# CH32H417 register map
Vendor: WCH Ltd.; File version: 1.2
Registers are 32-bit, read-write, reset 0x0 unless marked. A register's access mark holds for its fields unless they carry their own. Offsets are from the block's base; [hi:lo] are bit positions.

## ESIG — ESIG configuration
Base 0x1FFFF7E0
0x00 FLACAP 16-bit ro — Flash capecity register
  [15:0] F_SIZE — F_SIZE/kByte
0x08 UNIID1 ro — UID register
  [31:0] U_ID — U_ID value
0x0C UNIID2 ro — UID register
  [31:0] U_ID — U_ID value
0x10 UNIID3 ro — Div register
  [31:0] U_ID — U_ID value

## TIM6 — Basic timer
Base 0x40001000
Same registers: TIM7 0x40001400
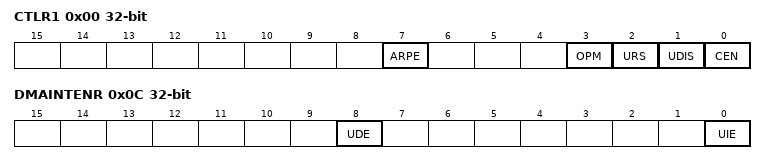
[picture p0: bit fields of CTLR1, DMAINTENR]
0x00 CTLR1 — control register 1
  [7] ARPE — Auto-reload preload enable
  [3] OPM — One-pulse mode
  [2] URS — Update request source
  [1] UDIS — Update disable
  [0] CEN — Counter enable
0x04 CTLR2 — control register 2
  [6:4] MMS — Master mode selection
0x0C DMAINTENR — DMA/Interrupt enable register
  [8] UDE — Update DMA request enable
  [0] UIE — Update interrupt enable
0x10 INTFR — status register
  [0] UIF — Update interrupt flag
0x14 SWEVGR wo — event generation register
  [0] UG — Update generation
0x24 CNT — counter
  [15:0] CNT — counter value
0x28 PSC — prescaler
  [15:0] PSC — Prescaler value
0x2C ATRLR reset 0xFFFF — auto-reload register
  [15:0] ARR — Auto-reload value

## LPTIM1 — Low-power timer 1
Base 0x40002400
Same registers: LPTIM2 0x40003400
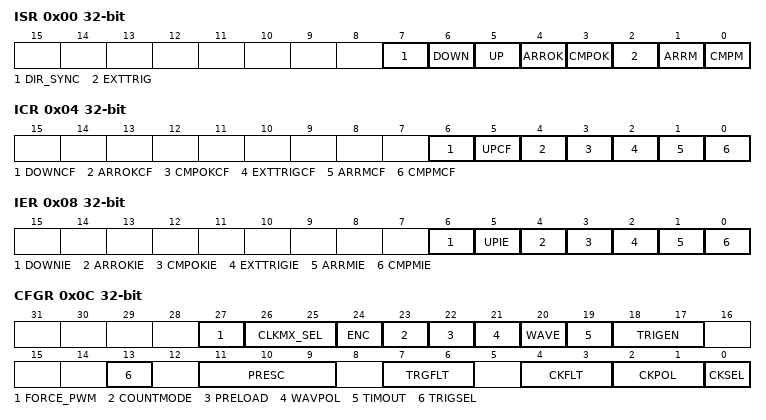
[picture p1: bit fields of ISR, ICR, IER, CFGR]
0x00 ISR ro — interrupt status register
  [7] DIR_SYNC — direction of count
  [6] DOWN — count down
  [5] UP — count-up
  [4] ARROK — Aoto-reload register data update successfully
  [3] CMPOK — compare register data update successfully
  [2] EXTTRIG — Edge event are triggerd externally
  [1] ARRM — DATA of Aoto-reload register and LPTIM_CNT match
  [0] CMPM — DATA of compare register and LPTIM_CNT match
0x04 ICR wo — interrupt clear register
  [6] DOWNCF — clear down flag
  [5] UPCF — clear up flag
  [4] ARROKCF — clear Aoto-reload register data update flag
  [3] CMPOKCF — clear compare register data update flag
  [2] EXTTRIGCF — clear Edge event are triggerd externally flag
  [1] ARRMCF — clear Aoto-reload register match flag
  [0] CMPMCF — clear compare register match flag
0x08 IER — interrupt enable register
  [6] DOWNIE — Down interrupt enable
  [5] UPIE — UP interrupt enable
  [4] ARROKIE — Aoto-reload register data update successfully interrupts enable
  [3] CMPOKIE — compare register data update successfully interrupts enable
  [2] EXTTRIGIE — Edge event are triggerd externally successfully interrupts enable
  [1] ARRMIE — Aoto-reload register match successfully interrupts enable
  [0] CMPMIE — compare register match successfully interrupts enable
0x0C CFGR — configuration register
  [27] FORCE_PWM — Forcing pwm output
  [26:25] CLKMX_SEL — clock selection
  [24] ENC — coder mode
  [23] COUNTMODE — count clock selection
  [22] PRELOAD — update mode control
  [21] WAVPOL — PWM polarity
  [20] WAVE — PWM
  [19] TIMOUT — TIMEOUT control
  [18:17] TRIGEN — trigger configuration
  [13] TRIGSEL — trigger source selection
  [11:9] PRESC — prescaler configuration
  [7:6] TRGFLT — digital filter for flip-flops
  [4:3] CKFLT — digital filter for ex-clock
  [2:1] CKPOL — configure effective edges
  [0] CKSEL — effective edge configuration
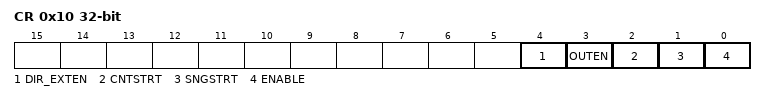
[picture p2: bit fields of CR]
0x10 CR — control register
  [4] DIR_EXTEN — externally trigger count direction enable
  [3] OUTEN — pwm output enable
  [2] CNTSTRT — start in continuous mode
  [1] SNGSTRT — start in one trigger mode
  [0] ENABLE — timer enable
0x14 CMP — compare register
  [15:0] CMP — compare value
0x18 ARR reset 0x1 — aoto-reload register
  [15:0] ARR — aoto-reload count value
0x1C CNT — COUNT register
  [15:0] COUNT — Timer count value

## DAC — Digital to analog converter
Base 0x40007400
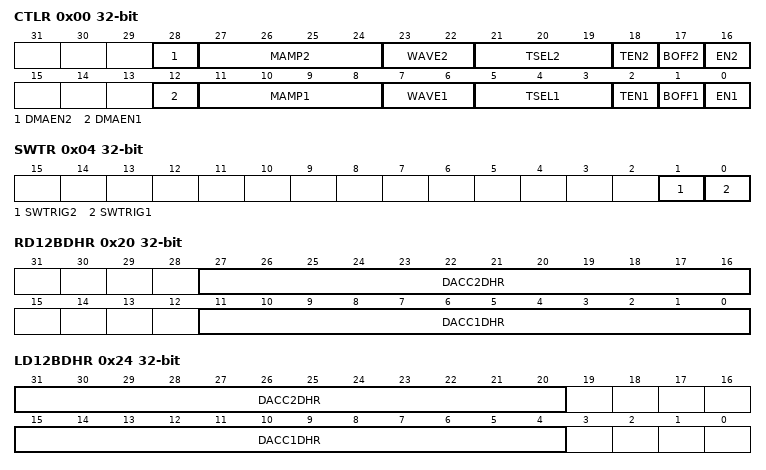
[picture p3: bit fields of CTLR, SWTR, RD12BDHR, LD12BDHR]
0x00 CTLR — Control register (DAC_CR)
  [28] DMAEN2 — DAC channel2 DMA enable
  [27:24] MAMP2 — DAC channel2 mask/amplitude selector
  [23:22] WAVE2 — DAC channel2 noise/triangle wave generation enable
  [21:19] TSEL2 — DAC channel2 trigger selection
  [18] TEN2 — DAC channel2 trigger enable
  [17] BOFF2 — DAC channel2 output buffer disable
  [16] EN2 — DAC channel2 enable
  [12] DMAEN1 — DAC channel1 DMA enable
  [11:8] MAMP1 — DAC channel1 mask/amplitude selector
  [7:6] WAVE1 — DAC channel1 noise/triangle wave generation enable
  [5:3] TSEL1 — DAC channel1 trigger selection
  [2] TEN1 — DAC channel1 trigger enable
  [1] BOFF1 — DAC channel1 output buffer disable
  [0] EN1 — DAC channel1 enable
0x04 SWTR wo — DAC software trigger register (DAC_SWTRIGR)
  [1] SWTRIG2 — DAC channel2 software trigger
  [0] SWTRIG1 — DAC channel1 software trigger
0x08 R12BDHR1 — DAC channel1 12-bit right-aligned data holding register(DAC_DHR12R1)
  [11:0] DACC1DHR — DAC channel1 12-bit right-aligned data
0x0C L12BDHR1 — DAC channel1 12-bit left aligned data holding register (DAC_DHR12L1)
  [15:4] DACC1DHR — DAC channel1 12-bit left-aligned data
0x10 R8BDHR1 — DAC channel1 8-bit right aligned data holding register (DAC_DHR8R1)
  [7:0] DACC1DHR — DAC channel1 8-bit right-aligned data
0x14 R12BDHR2 — DAC channel2 12-bit right aligned data holding register (DAC_DHR12R2)
  [11:0] DACC2DHR — DAC channel2 12-bit right-aligned data
0x18 L12BDHR2 — DAC channel2 12-bit left aligned data holding register (DAC_DHR12L2)
  [15:4] DACC2DHR — DAC channel2 12-bit left-aligned data
0x1C R8BDHR2 — DAC channel2 8-bit right-aligned data holding register (DAC_DHR8R2)
  [7:0] DACC2DHR — DAC channel2 8-bit right-aligned data
0x20 RD12BDHR — Dual DAC 12-bit right-aligned data holding register (DAC_DHR12RD), Bits 31:28 Reserved, Bits 15:12 Reserved
  [27:16] DACC2DHR — DAC channel2 12-bit right-aligned data
  [11:0] DACC1DHR — DAC channel1 12-bit right-aligned data
0x24 LD12BDHR — DUAL DAC 12-bit left aligned data holding register (DAC_DHR12LD), Bits 19:16 Reserved, Bits 3:0 Reserved
  [31:20] DACC2DHR — DAC channel2 12-bit right-aligned data
  [15:4] DACC1DHR — DAC channel1 12-bit left-aligned data
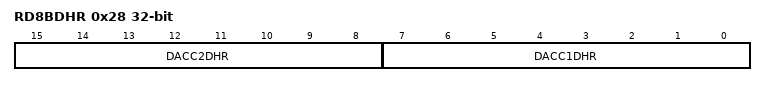
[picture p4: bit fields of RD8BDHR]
0x28 RD8BDHR — DUAL DAC 8-bit right aligned data holding register (DAC_DHR8RD), Bits 31:16 Reserved
  [15:8] DACC2DHR — DAC channel2 8-bit right-aligned data
  [7:0] DACC1DHR — DAC channel1 8-bit right-aligned data
0x2C DOR1 ro — DAC channel1 data output register (DAC_DOR1)
  [11:0] DACC1DOR — DAC channel1 data output
0x30 DOR2 ro — DAC channel2 data output register (DAC_DOR2)
  [11:0] DACC2DOR — DAC channel2 data output
